# TM4C123GH6PM register map
Vendor: Texas Instruments; Series: TM4C; File version: 11073
CPU: CM4 r1p2, little endian, MPU, FPU, 3 interrupt priority bits
Registers are 32-bit, read-write, reset 0x1 unless marked. A register's access mark holds for its fields unless they carry their own. Offsets are from the block's base; [hi:lo] are bit positions; {n}, {i} and the like mark numbered series.

## EEPROM — Register map for EEPROM peripheral
Base 0x400AF000; register names take the prefix EEPROM
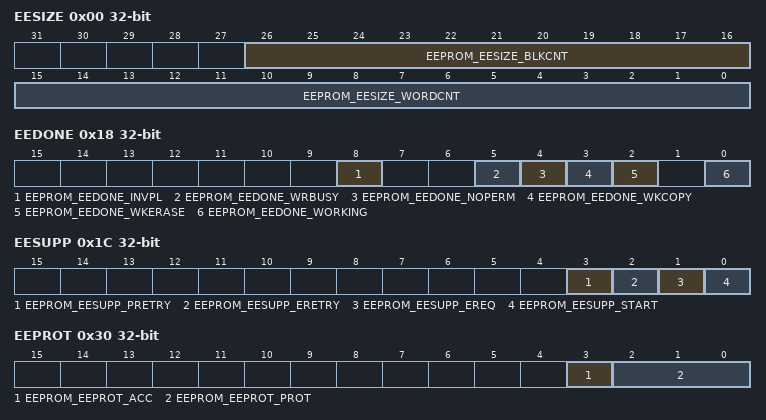
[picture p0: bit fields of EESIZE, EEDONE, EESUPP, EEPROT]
0x00 EESIZE (reset mask 0x0) — EEPROM Size Information
  [26:16] EEPROM_EESIZE_BLKCNT — Number of 16-Word Blocks
  [15:0] EEPROM_EESIZE_WORDCNT — Number of 32-Bit Words
0x04 EEBLOCK (reset mask 0x0) — EEPROM Current Block
  [15:0] EEPROM_EEBLOCK_BLOCK — Current Block
0x08 EEOFFSET (reset mask 0x0) — EEPROM Current Offset
  [3:0] EEPROM_EEOFFSET_OFFSET — Current Address Offset
0x10 EERDWR (reset mask 0x0) — EEPROM Read-Write
  [31:0] EEPROM_EERDWR_VALUE — EEPROM Read or Write Data
0x14 EERDWRINC (reset mask 0x0) — EEPROM Read-Write with Increment
  [31:0] EEPROM_EERDWRINC_VALUE — EEPROM Read or Write Data with Increment
0x18 EEDONE (reset mask 0x0) — EEPROM Done Status
  [8] EEPROM_EEDONE_INVPL — Invalid Program Voltage Level
  [5] EEPROM_EEDONE_WRBUSY — Write Busy
  [4] EEPROM_EEDONE_NOPERM — Write Without Permission
  [3] EEPROM_EEDONE_WKCOPY — Working on a Copy
  [2] EEPROM_EEDONE_WKERASE — Working on an Erase
  [0] EEPROM_EEDONE_WORKING — EEPROM Working
0x1C EESUPP (reset mask 0x0) — EEPROM Support Control and Status
  [3] EEPROM_EESUPP_PRETRY — Programming Must Be Retried
  [2] EEPROM_EESUPP_ERETRY — Erase Must Be Retried
  [1] EEPROM_EESUPP_EREQ — Erase Required
  [0] EEPROM_EESUPP_START — Start Erase
0x20 EEUNLOCK (reset mask 0x0) — EEPROM Unlock
  [31:0] EEPROM_EEUNLOCK_UNLOCK
0x30 EEPROT (reset mask 0x0) — EEPROM Protection
  [3] EEPROM_EEPROT_ACC — Access Control
  [2:0] EEPROM_EEPROT_PROT — Protection Control
    0=EEPROM_EEPROT_PROT_RWNPW (This setting is the default. If there is no password, the block is not protected and is readable and writable); 1=EEPROM_EEPROT_PROT_RWPW (If there is a password, the block is readable or writable only when unlocked); 2=EEPROM_EEPROT_PROT_RONPW (If there is no password, the block is readable, not writable)
{0x34+4i} EEPASS{i} (reset mask 0x0) (i=0..2) — EEPROM Password
  [31:0] EEPROM_EEPASS{i}_PASS — Password
0x40 EEINT (reset mask 0x0) — EEPROM Interrupt
  [0] EEPROM_EEINT_INT — Interrupt Enable
0x50 EEHIDE (reset mask 0x0) — EEPROM Block Hide
  [31:1] EEPROM_EEHIDE_HN — Hide Block
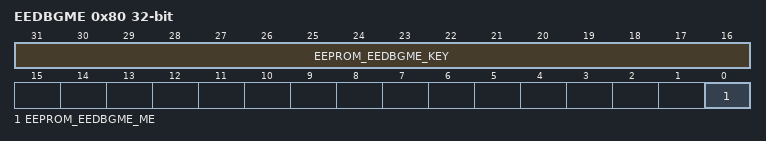
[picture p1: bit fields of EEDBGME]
0x80 EEDBGME (reset mask 0x0) — EEPROM Debug Mass Erase
  [31:16] EEPROM_EEDBGME_KEY — Erase Key
  [0] EEPROM_EEDBGME_ME — Mass Erase
0xFC0 PP (reset mask 0x0) — EEPROM Peripheral Properties
  [4:0] EEPROM_PP_SIZE — EEPROM Size

## SYSEXC — Register map for SYSEXC peripheral
Base 0x400F9000; register names take the prefix SYSEXC
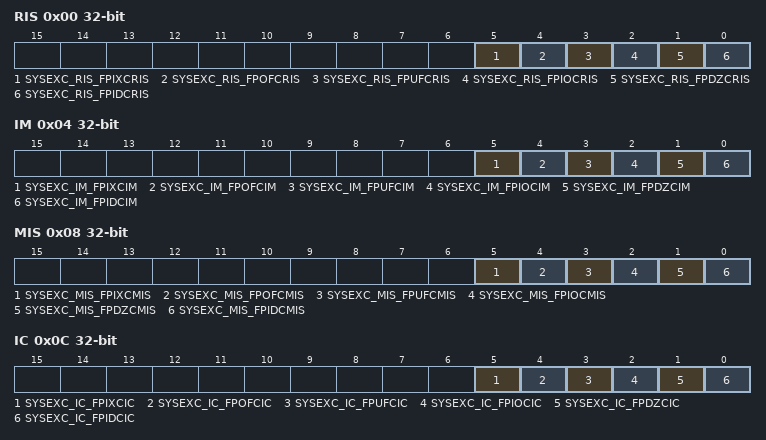
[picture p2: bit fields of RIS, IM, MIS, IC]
0x00 RIS (reset mask 0x0) — System Exception Raw Interrupt Status
  [5] SYSEXC_RIS_FPIXCRIS — Floating-Point Inexact Exception Raw Interrupt Status
  [4] SYSEXC_RIS_FPOFCRIS — Floating-Point Overflow Exception Raw Interrupt Status
  [3] SYSEXC_RIS_FPUFCRIS — Floating-Point Underflow Exception Raw Interrupt Status
  [2] SYSEXC_RIS_FPIOCRIS — Floating-Point Invalid Operation Raw Interrupt Status
  [1] SYSEXC_RIS_FPDZCRIS — Floating-Point Divide By 0 Exception Raw Interrupt Status
  [0] SYSEXC_RIS_FPIDCRIS — Floating-Point Input Denormal Exception Raw Interrupt Status
0x04 IM (reset mask 0x0) — System Exception Interrupt Mask
  [5] SYSEXC_IM_FPIXCIM — Floating-Point Inexact Exception Interrupt Mask
  [4] SYSEXC_IM_FPOFCIM — Floating-Point Overflow Exception Interrupt Mask
  [3] SYSEXC_IM_FPUFCIM — Floating-Point Underflow Exception Interrupt Mask
  [2] SYSEXC_IM_FPIOCIM — Floating-Point Invalid Operation Interrupt Mask
  [1] SYSEXC_IM_FPDZCIM — Floating-Point Divide By 0 Exception Interrupt Mask
  [0] SYSEXC_IM_FPIDCIM — Floating-Point Input Denormal Exception Interrupt Mask
0x08 MIS (reset mask 0x0) — System Exception Masked Interrupt Status
  [5] SYSEXC_MIS_FPIXCMIS — Floating-Point Inexact Exception Masked Interrupt Status
  [4] SYSEXC_MIS_FPOFCMIS — Floating-Point Overflow Exception Masked Interrupt Status
  [3] SYSEXC_MIS_FPUFCMIS — Floating-Point Underflow Exception Masked Interrupt Status
  [2] SYSEXC_MIS_FPIOCMIS — Floating-Point Invalid Operation Masked Interrupt Status
  [1] SYSEXC_MIS_FPDZCMIS — Floating-Point Divide By 0 Exception Masked Interrupt Status
  [0] SYSEXC_MIS_FPIDCMIS — Floating-Point Input Denormal Exception Masked Interrupt Status
0x0C IC wo (reset mask 0x0) — System Exception Interrupt Clear
  [5] SYSEXC_IC_FPIXCIC — Floating-Point Inexact Exception Interrupt Clear
  [4] SYSEXC_IC_FPOFCIC — Floating-Point Overflow Exception Interrupt Clear
  [3] SYSEXC_IC_FPUFCIC — Floating-Point Underflow Exception Interrupt Clear
  [2] SYSEXC_IC_FPIOCIC — Floating-Point Invalid Operation Interrupt Clear
  [1] SYSEXC_IC_FPDZCIC — Floating-Point Divide By 0 Exception Interrupt Clear
  [0] SYSEXC_IC_FPIDCIC — Floating-Point Input Denormal Exception Interrupt Clear

## HIB — Register map for HIB peripheral
Base 0x400FC000; register names take the prefix HIB
0x00 RTCC (reset mask 0x0) — Hibernation RTC Counter
  [31:0] HIB_RTCC — RTC Counter
0x04 RTCM0 (reset mask 0x0) — Hibernation RTC Match 0
  [31:0] HIB_RTCM0 — RTC Match 0
0x0C RTCLD (reset mask 0x0) — Hibernation RTC Load
  [31:0] HIB_RTCLD — RTC Load
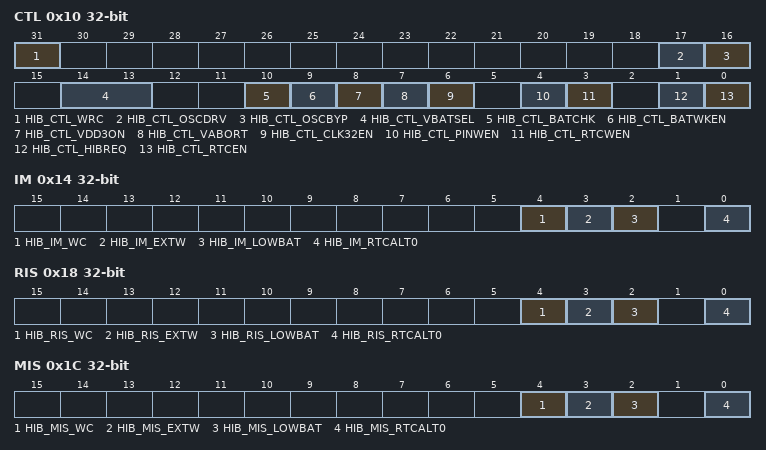
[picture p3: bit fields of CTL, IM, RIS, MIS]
0x10 CTL (reset mask 0x0) — Hibernation Control
  [31] HIB_CTL_WRC — Write Complete/Capable
  [17] HIB_CTL_OSCDRV — Oscillator Drive Capability
  [16] HIB_CTL_OSCBYP — Oscillator Bypass
  [14:13] HIB_CTL_VBATSEL — Select for Low-Battery Comparator
    0=HIB_CTL_VBATSEL_1_9V (1.9 Volts); 1=HIB_CTL_VBATSEL_2_1V (2.1 Volts (default)); 2=HIB_CTL_VBATSEL_2_3V (2.3 Volts); 3=HIB_CTL_VBATSEL_2_5V (2.5 Volts)
  [10] HIB_CTL_BATCHK — Check Battery Status
  [9] HIB_CTL_BATWKEN — Wake on Low Battery
  [8] HIB_CTL_VDD3ON — VDD Powered
  [7] HIB_CTL_VABORT — Power Cut Abort Enable
  [6] HIB_CTL_CLK32EN — Clocking Enable
  [4] HIB_CTL_PINWEN — External WAKE Pin Enable
  [3] HIB_CTL_RTCWEN — RTC Wake-up Enable
  [1] HIB_CTL_HIBREQ — Hibernation Request
  [0] HIB_CTL_RTCEN — RTC Timer Enable
0x14 IM (reset mask 0x0) — Hibernation Interrupt Mask
  [4] HIB_IM_WC — External Write Complete/Capable Interrupt Mask
  [3] HIB_IM_EXTW — External Wake-Up Interrupt Mask
  [2] HIB_IM_LOWBAT — Low Battery Voltage Interrupt Mask
  [0] HIB_IM_RTCALT0 — RTC Alert 0 Interrupt Mask
0x18 RIS (reset mask 0x0) — Hibernation Raw Interrupt Status
  [4] HIB_RIS_WC — Write Complete/Capable Raw Interrupt Status
  [3] HIB_RIS_EXTW — External Wake-Up Raw Interrupt Status
  [2] HIB_RIS_LOWBAT — Low Battery Voltage Raw Interrupt Status
  [0] HIB_RIS_RTCALT0 — RTC Alert 0 Raw Interrupt Status
0x1C MIS (reset mask 0x0) — Hibernation Masked Interrupt Status
  [4] HIB_MIS_WC — Write Complete/Capable Masked Interrupt Status
  [3] HIB_MIS_EXTW — External Wake-Up Masked Interrupt Status
  [2] HIB_MIS_LOWBAT — Low Battery Voltage Masked Interrupt Status
  [0] HIB_MIS_RTCALT0 — RTC Alert 0 Masked Interrupt Status
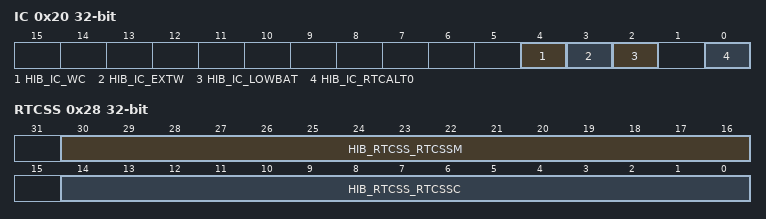
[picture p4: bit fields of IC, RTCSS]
0x20 IC (reset mask 0x0) — Hibernation Interrupt Clear
  [4] HIB_IC_WC — Write Complete/Capable Masked Interrupt Clear
  [3] HIB_IC_EXTW — External Wake-Up Masked Interrupt Clear
  [2] HIB_IC_LOWBAT — Low Battery Voltage Masked Interrupt Clear
  [0] HIB_IC_RTCALT0 — RTC Alert0 Masked Interrupt Clear
0x24 RTCT (reset mask 0x0) — Hibernation RTC Trim
  [15:0] HIB_RTCT_TRIM — RTC Trim Value
0x28 RTCSS (reset mask 0x0) — Hibernation RTC Sub Seconds
  [30:16] HIB_RTCSS_RTCSSM — RTC Sub Seconds Match
  [14:0] HIB_RTCSS_RTCSSC — RTC Sub Seconds Count
0x30 DATA (reset mask 0x0) — Hibernation Data
  [31:0] HIB_DATA_RTD — Hibernation Module NV Data
